# C6424_cslr_psc_001 register map
Vendor: Texas Instruments
Peripheral module from a debugger description file.
Registers are 32-bit, read-only, reset 0x0 unless marked. A register's access mark holds for its fields unless they carry their own. Offsets are as the file gives them; lines under a group give offsets from that group; [hi:lo] are bit positions; {n}, {i} and the like mark numbered series; 'fields as' and 'values as' point back to an identical list; <NAME> marks a mode.

## PSC — Power and Sleep Controller (PSC) Version 0.95
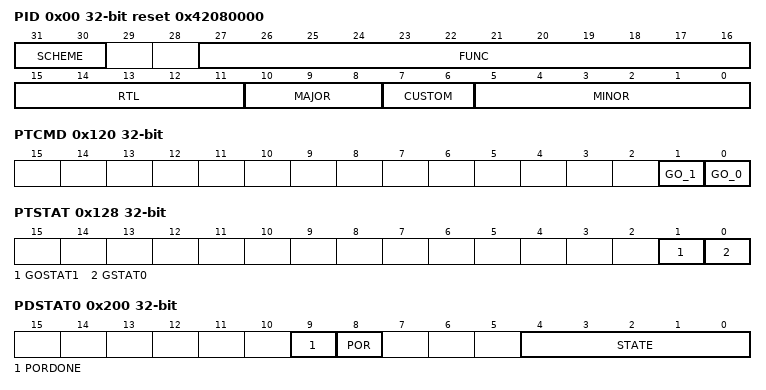
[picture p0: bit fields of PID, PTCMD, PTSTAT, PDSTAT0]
0x00 PID reset 0x42080000 — Peripheral Revision and Class Information
  [31:30] SCHEME — Used to distinguish between old scheme and current. Spare bit to encode future schemes
  [27:16] FUNC — Indicating a software compatible module family. If there is no level of software compatibility a new ID should be assigned.
  [15:11] RTL — RTL Version. (R as described in PDR 9.3.2) Must be easily ECO'able or controlled during fabrication. Ideally through a top level metal mask or efuse. Start with 0 for PSC1.0, 1 for PSC2.0
  [10:8] MAJOR — Major Revision.
  [7:6] CUSTOM — Indicates a Special Version for a particular device. Consequence of use may avoid use of standard CSL/Drivers. 0 if non-custom
  [5:0] MINOR — Minor Revision Must be easily ECO'able or controlled during fabrication. Ideally through a top level metal mask or efuse. Start with 0.
0x18 INTEVAL access per field — Interrupt Evaluation Register
  [0] ALLEV wo — Evaluate PSC interrupt 0: Write of 0 has no effect 1: Write of 1 re-evaluate the combined PSC interrupt PSC_ALLINT
0x44 MERRPR1 — Module Error Pending 1 (mod 33) Register
  [1] M_33 — Module interrupt status bit for module 33 (C64x+ CPU).
0x54 MERRCR1 — Module Error Clear 1 (mod 33) Register
  [1] M_33 — Clears the interrupt status bits set in the corresponding module error pending register 1 (mod 33) (MERRPR1) and the module status 33 register (MDSTAT33). This pertains to module 33.
0x120 PTCMD access per field — Power Domain Transition Command Register
  [1] GO_1 rw — AlwaysOn power domain GO Transition command
  [0] GO_0 rw — AlwaysOn power domain GO Transition command
0x128 PTSTAT access per field — Power Domain Transition Status Register
  [1] GOSTAT1 rw — Ethernet Subsystem Power domain transition status
  [0] GSTAT0 rw — AlwaysOn Power domain transition status.
0x200 PDSTAT0 — Power Domain Status 0 Register
  [9] PORDONE — power on Reset done status
  [8] POR — Power domain Power_On_Reset (POR) status. This bit reflects the POR status for this power domain including all modules in the domain
  [4:0] STATE — Power Domain Status
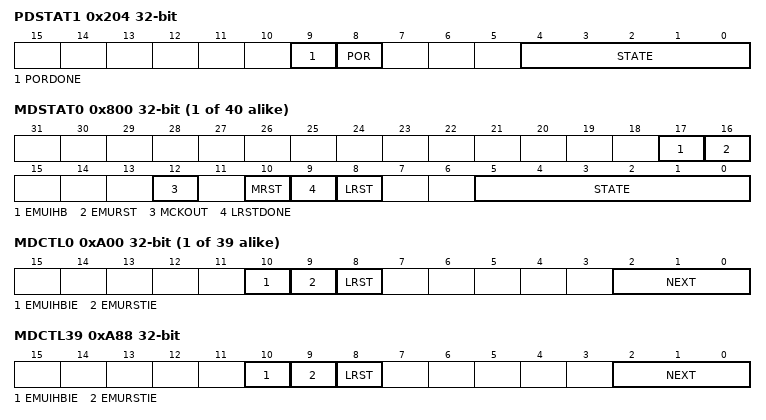
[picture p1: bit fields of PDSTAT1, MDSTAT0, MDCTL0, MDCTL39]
0x204 PDSTAT1 — Power Domain Status 1 Register
  fields as PDSTAT0
0x300 PDCTL0 access per field — Power Domain Control 0 Register
  [0] NEXT rw — User-Desired Next Power Domain State 0: Off 1: On
0x300 PDCTL1 access per field — Power Domain Control 1 Register
  [0] NEXT rw — User-Desired Next Power Domain State 0: Off 1: On
{0x800+4i} MDSTAT{i} (i=0..39) — Module Status {i} Register
  [17] EMUIHB — Emulation Alters Module State - Inhibits Module Inactive or Force Module Active 0: No emulation altering user-desired module state 1: Emulation alters user-desired module state
  [16] EMURST — Emulation Alters Reset (lrst or mrst) to Module 0: No emulation altering user-desired reset 1: Emulation alters user-desired module state
  [12] MCKOUT — Module clock output status. Shows actual status of module clock.
  [10] MRST — Module reset status. Reflects actual state of module reset
  [9] LRSTDONE — Local reset done. Software is responsible for checking if local reset is done before accessing this module. This bit applies to the DSP module only (module 39). This field is 1 for all other modules.
  [8] LRST — Module local reset status. This bit applies to the DSP module only (module 39).
  [5:0] STATE — Module state status. Indicates current module status
{0xA00+4i} MDCTL{i} access per field (i=0..38) — Module Control {i} Register
  [10] EMUIHBIE rw — Interrupt enable for emulation alters module state. This bit applies to the DSP module only (module 39).Program this field to 0 for all other modules 0: Not enabled 1: Interrupt enabled
  [9] EMURSTIE rw — Emulation Alter Reset Interrupt Enable 0: Not enabled 1: Interrupt Enabled
  [8] LRST rw — Module local reset control (only applicable to some modules -- e.g GEM, BCG EMIF) 0: Assert local reset 1: De-assert local reset
  [2:0] NEXT rw — Module Next State 000: SwRstDisable 001: Disable 010: SyncReset 011: Enable 100: Reserved/Invalid 101: Sleep 110: Reserved/Invalid 111: Reserved/Invalid
0xA88 MDCTL39 access per field — Module Control 39 Register
  fields as MDCTL0
